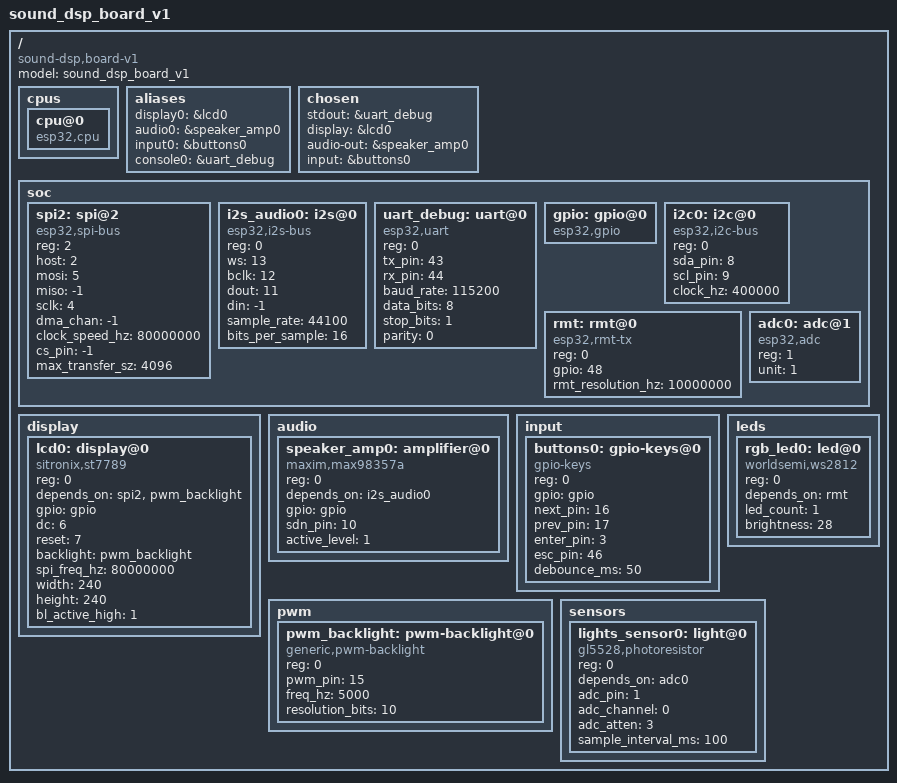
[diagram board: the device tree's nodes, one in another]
/dts-v1/;

/ {
    compatible = "sound-dsp,board-v1";
    #address-cells = <1>;
    #size-cells = <0>;
    model = "sound_dsp_board_v1";

    cpus {
        cpu@0 {
            compatible = "esp32,cpu";
        };
    };

    aliases {
        display0 = &lcd0;
        audio0 = &speaker_amp0;
        input0 = &buttons0;
        console0 = &uart_debug;
    };

    chosen {
        stdout = &uart_debug;
        display = &lcd0;
        audio-out = &speaker_amp0;
        input = &buttons0;
    };

    soc {
        spi2: spi@2 {
            reg = <2>;
            compatible = "esp32,spi-bus";
            host = <2>;
            mosi = <5>;
            miso = <-1>;
            sclk = <4>;
            dma_chan = <-1>;
            clock_speed_hz = <80000000>;
            cs_pin = <-1>;
            max_transfer_sz = <4096>;
        };

        i2s_audio0: i2s@0 {
            reg = <0>;
            compatible = "esp32,i2s-bus";
            ws = <13>;
            bclk = <12>;
            dout = <11>;
            din = <-1>;
            sample_rate = <44100>;
            bits_per_sample = <16>;
        };

        uart_debug: uart@0 {
            reg = <0>;
            compatible = "esp32,uart";
            tx_pin = <43>;
            rx_pin = <44>;
            baud_rate = <115200>;
            data_bits = <8>;
            stop_bits = <1>;
            parity = <0>;
        };

        gpio: gpio@0 {
            compatible = "esp32,gpio";
        };

        i2c0: i2c@0 {
            reg = <0>;
            compatible = "esp32,i2c-bus";
            sda_pin = <8>;
            scl_pin = <9>;
            clock_hz = <400000>;
        };

        rmt: rmt@0 {
            reg = <0>;
            compatible = "esp32,rmt-tx";
            gpio = <48>;
            rmt_resolution_hz = <10000000>;
        };

        adc0: adc@1 {
            reg = <1>;
            compatible = "esp32,adc";
            unit = <1>;
        };
    };

    display {
        lcd0: display@0 {
            reg = <0>;
            compatible = "sitronix,st7789";
            depends_on = <&spi2>, <&pwm_backlight>;
            gpio = <&gpio>;
            dc = <6>;
            reset = <7>;
            backlight = <&pwm_backlight>;
            spi_freq_hz = <80000000>;
            width = <240>;
            height = <240>;
            bl_active_high = <1>;
        };
    };

    audio {
        speaker_amp0: amplifier@0 {
            reg = <0>;
            compatible = "maxim,max98357a";
            depends_on = <&i2s_audio0>;
            gpio = <&gpio>;
            sdn_pin = <10>;
            active_level = <1>;
        };
    };

    input {
        buttons0: gpio-keys@0 {
            reg = <0>;
            compatible = "gpio-keys";
            gpio = <&gpio>;
            next_pin = <16>;
            prev_pin = <17>;
            enter_pin = <3>;
            esc_pin = <46>;
            debounce_ms = <50>;
        };
    };

    pwm {
        pwm_backlight: pwm-backlight@0 {
            reg = <0>;
            compatible = "generic,pwm-backlight";
            pwm_pin = <15>;
            freq_hz = <5000>;
            resolution_bits = <10>;
            status = "okay";
        };
    };

    leds {
        rgb_led0: led@0 {
            reg = <0>;
            compatible = "worldsemi,ws2812";
            depends_on = <&rmt>;
            led_count = <1>;
            brightness = <28>;
        };
    };

    sensors {
        lights_sensor0: light@0 {
            reg = <0>;
            compatible = "gl5528,photoresistor";
            depends_on = <&adc0>;
            adc_pin = <1>;
            adc_channel = <0>;
            adc_atten = <3>;  // 11dB attenuation (0~3.9V范围)
            sample_interval_ms = <100>;
            status = "okay";
        };
    };
};
